AUTOSAR XML (schema 00044)
package /NvAResourceConsumption/SwAddrMethods
  sw addr method CODE: memory-allocation-keyword-policy=ADDR-METHOD-SHORT-NAME, section-type=CODE
  sw addr method CONST: memory-allocation-keyword-policy=ADDR-METHOD-SHORT-NAME-AND-ALIGNMENT, section-type=CONST
package /ComponentTypes
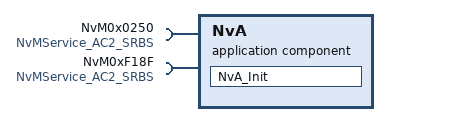
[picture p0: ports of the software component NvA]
  application sw component type NvA
    require port NvM0x0250: required-com-specs=[GetErrorStatus, ReadBlock, SetRamBlockStatus, WriteBlock], required-interface=NvMService_AC2_SRBS
    require port NvM0xF18F: required-com-specs=[GetErrorStatus, ReadBlock, SetRamBlockStatus, WriteBlock], required-interface=NvMService_AC2_SRBS
    behavior NvA_InternalBehavior
      init event NvA_InitEvent: start-on-event=NvA_Init
      runnable NvA_Init
        6 x sync call, all with timeout=0:
          SC_NvM_Service_0x0250_Integrity_validation_data_configuration_list_GetErrorStatus: operation=NvM0x0250.GetErrorStatus
          SC_NvM_Service_0x0250_Integrity_validation_data_configuration_list_ReadBlock: operation=NvM0x0250.ReadBlock
          SC_NvM_Service_0x0250_Integrity_validation_data_configuration_list_WriteBlock: operation=NvM0x0250.WriteBlock
          SC_Nvm_Service_0xF18F_Regulation_x_software_identification_numbers_GetErrorStatus: operation=NvM0xF18F.GetErrorStatus
          SC_Nvm_Service_0xF18F_Regulation_x_software_identification_numbers_ReadBlock: operation=NvM0xF18F.ReadBlock
          SC_Nvm_Service_0xF18F_Regulation_x_software_identification_numbers_WriteBlock: operation=NvM0xF18F.WriteBlock
  swc implementation NvA_Implementation: vendor-id=75, behavior=NvA_InternalBehavior
    code-descriptors:
      code Default: artifact-descriptors=autosar-engineering-object={short-label=Default, category=SWSRC}
    resource consumption ResourceConsumption
      memory section CODE: sw-addrmethod=CODE
      memory section CONST_UNSPECIFIED: alignment=UNSPECIFIED, sw-addrmethod=CONST
package /Predefined_DEV/ImplementationDataTypes
  impl type NvM_RequestResultType: compu {0=NVM_REQ_OK, 1=NVM_REQ_NOT_OK, 2=NVM_REQ_PENDING, 3=NVM_REQ_INTEGRITY_FAILED, 4=NVM_REQ_BLOCK_SKIPPED, 5=NVM_REQ_NV_INVALIDATED, 6=NVM_REQ_CANCELED, 7=NVM_REQ_REDUNDANCY_FAILED, 8=NVM_REQ_RESTORED_FROM_ROM}, implementation-data-type=uint8
package /Predefined_DEV/PortInterfaces
  client server interface NvMService_AC2_SRBS: is-service=true
    4 x operation, all with possible-error=E_NOT_OK:
      GetErrorStatus
        arg ErrorStatus: type=NvM_RequestResultType, direction=OUT, server-argument-impl-policy=USE-ARGUMENT-TYPE
      ReadBlock
        arg DstPtr: type=dtRef_VOID, direction=IN, server-argument-impl-policy=USE-ARGUMENT-TYPE
      SetRamBlockStatus
        arg RamBlockStatus: type=boolean, direction=IN, server-argument-impl-policy=USE-ARGUMENT-TYPE
      WriteBlock
        arg SrcPtr: type=dtRef_const_VOID, direction=IN, server-argument-impl-policy=USE-ARGUMENT-TYPE
    error E_NOT_OK: error-code=1
